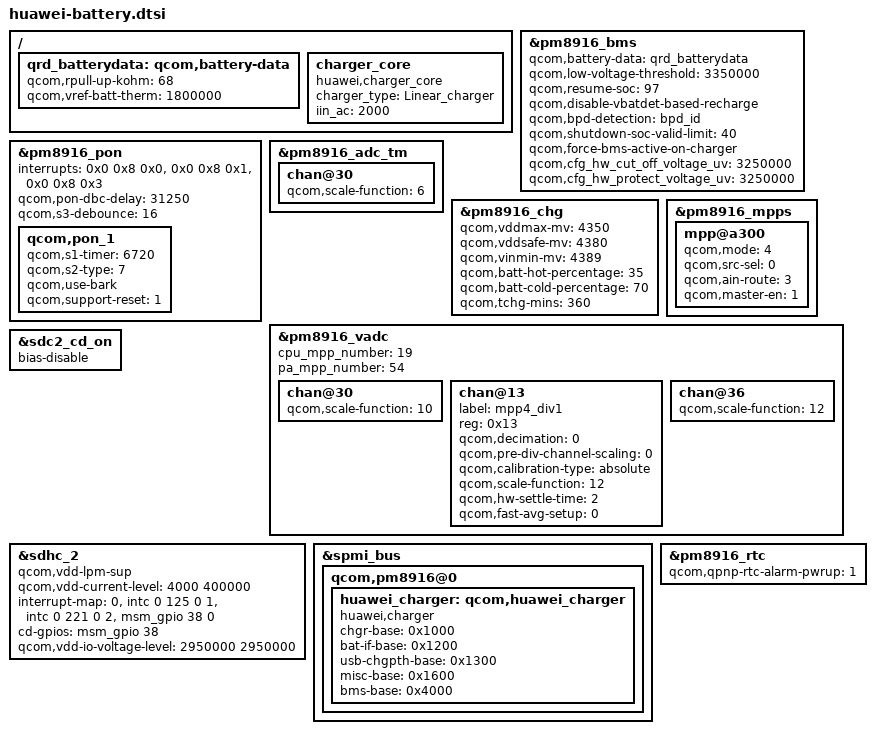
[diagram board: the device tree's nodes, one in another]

/ {
	qrd_batterydata: qcom,battery-data {
		qcom,rpull-up-kohm = <68>;
		qcom,vref-batt-therm = <1800000>;
                #include "HB474284RBC_BYD_BYD-4v35-2000mah.dtsi"
                #include "HB474284RBC_LG_SCUD-4v35-2000mah.dtsi"
	};
};

&pm8916_bms {
	status = "ok";
	qcom,battery-data = <&qrd_batterydata>;
	qcom,low-voltage-threshold = <3350000>;
	qcom,resume-soc = <97>;
	qcom,disable-vbatdet-based-recharge;
	qcom,bpd-detection = "bpd_id";
	qcom,shutdown-soc-valid-limit = <40>;
	qcom,force-bms-active-on-charger;
	qcom,cfg_hw_cut_off_voltage_uv = <3250000>;
	qcom,cfg_hw_protect_voltage_uv = <3250000>;
};

&pm8916_pon {
	interrupts = <0x0 0x8 0x0>,
		     <0x0 0x8 0x1>,
		     <0x0 0x8 0x3>;
	interrupt-names = "kpdpwr", "resin", "kpdpwr-bark";
	qcom,pon-dbc-delay = <31250>;
	qcom,s3-debounce = <16>;
	qcom,pon_1 {
		qcom,s1-timer = <6720>;
		/*change s2 timer reset source to hw reset*/
		qcom,s2-type = <7>; /* hard reset */
		qcom,use-bark;
		qcom,support-reset = <1>;
	};
};

&pm8916_adc_tm {
	chan@30 {
		qcom,scale-function = <6>;
	};
};

&pm8916_chg {
	qcom,vddmax-mv = <4350>;
	qcom,vddsafe-mv = <4380>;
	qcom,vinmin-mv = <4389>;
	qcom,batt-hot-percentage = <35>;
	qcom,batt-cold-percentage = <70>;
	qcom,tchg-mins = <360>;
	status = "okay";
};

&pm8916_mpps {
	mpp@a300 {
		qcom,mode = <4>; // QPNP_PIN_MODE_AIN
		qcom,src-sel = <0>; // QPNP_PIN_SEL_FUNC_CONSTANT
		qcom,ain-route = <3>; // QPNP_PIN_AIN_AMUX_CH8
		qcom,master-en = <1>; // Enable features
	};
};

&pm8916_vadc {
	cpu_mpp_number = <19>;
	pa_mpp_number = <54>;

	chan@30 {
		qcom,scale-function = <10>;
	};

	chan@13 {
		label = "mpp4_div1";
		reg = <0x13>;
		qcom,decimation = <0>; //512 sampling rate
		qcom,pre-div-channel-scaling = <0>; //1:1 scaling
		qcom,calibration-type = "absolute"; //Use 625mV & 1.25V reference voltage
		qcom,scale-function = <12>; //convert raw adc code to voltage
		qcom,hw-settle-time = <2>; //200us
		qcom,fast-avg-setup = <0>; //with only one average measurement
	};

	chan@36 {
		qcom,scale-function = <12>;
	};
};

&sdc2_cd_on {
	/delete-property/ bias-pull-up;
	bias-disable;
};

&sdhc_2 {
	qcom,vdd-lpm-sup;
	qcom,vdd-current-level = <4000 400000>;

	interrupt-map = <0 &intc 0 125 0
		1 &intc 0 221 0
		2 &msm_gpio 38 0>;
	cd-gpios = <&msm_gpio 38 0x0>;
	/delete-property/ qcom,vdd-io-always-on;
	/* As the limit of hardware, remove the support of uhs */
	qcom,vdd-io-voltage-level = <2950000 2950000>;
};

/{
	charger_core: charger_core{
		compatible = "huawei,charger_core";
		charger_type = "Linear_charger";
		iin_ac = <2000>;
		status = "ok";
	};
};

&spmi_bus{
	qcom,pm8916@0 {
		huawei_charger: qcom,huawei_charger{
			compatible = "huawei,charger";
			chgr-base = <0x1000>;
			bat-if-base = <0x1200>;
			usb-chgpth-base = <0x1300>;
			misc-base = <0x1600>;
			bms-base = <0x4000>;
			status = "ok";
		};
	};
};

&pm8916_rtc {
	qcom,qpnp-rtc-alarm-pwrup = <1>;
};
